VERSION "ECM CAN realtime data broadcast protocol 2016-02-17, section 2.1"

NS_ :

BS_:

BU_: WCM ECM RPI PDM

BO_ 768 PDM_status_group_1: 8 PDM
 SG_ pcba_temp_3 : 63|8@0- (1,0) [-128|127] "deg C"  RPI
 SG_ pcba_temp_2 : 55|8@0- (1,0) [-128|127] "deg C"  RPI
 SG_ pcba_temp_1 : 47|8@0- (1,0) [-128|127] "deg C"  RPI
 SG_ cpu_temp : 39|8@0- (1,0) [-128|127] "deg C"  RPI
 SG_ ac_status : 25|2@0+ (1,0) [0|3] ""  RPI
 SG_ ac_compressor_output : 26|1@0+ (1,0) [0|1] ""  RPI
 SG_ ac_command : 27|1@0+ (1,0) [0|1] ""  RPI
 SG_ blower_output : 29|2@0+ (1,0) [0|3] ""  RPI
 SG_ blower_command : 31|2@0+ (1,0) [0|3] ""  RPI
 SG_ window_state_rightt : 19|4@0+ (1,0) [0|15] ""  RPI
 SG_ window_state_left : 23|4@0+ (1,0) [0|15] ""  RPI
 SG_ wiper_state : 9|2@0+ (1,0) [0|3] ""  RPI
 SG_ turn_state_right : 11|2@0+ (1,0) [0|3] ""  RPI
 SG_ turn_state_left : 13|2@0+ (1,0) [0|3] ""  RPI
 SG_ headlight_state : 15|2@0+ (1,0) [0|3] ""  RPI
 SG_ key_status : 1|2@0+ (1,0) [0|3] ""  RPI
 SG_ power_wake_reason : 4|3@0+ (1,0) [0|7] ""  RPI
 SG_ power_state : 7|3@0+ (1,0) [0|7] ""  RPI

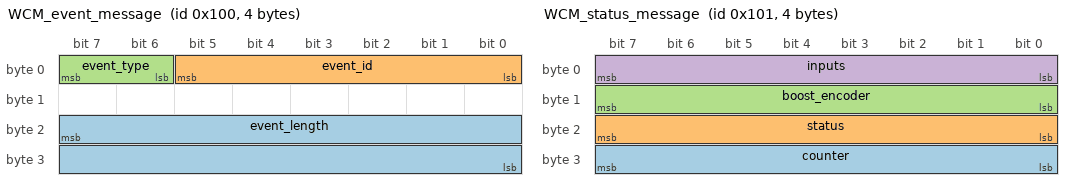
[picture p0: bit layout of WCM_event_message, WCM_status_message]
BO_ 256 WCM_event_message: 4 WCM
 SG_ event_length : 23|16@0+ (1,0) [0|65535] "ms"  RPI,PDM
 SG_ event_id : 5|6@0+ (1,0) [0|7] ""  RPI,PDM
 SG_ event_type : 7|2@0+ (1,0) [0|1] ""  RPI,PDM

BO_ 257 WCM_status_message: 4 WCM
 SG_ counter : 31|8@0+ (1,0) [0|255] ""  RPI,PDM,WCM
 SG_ status : 23|8@0+ (1,0) [0|255] ""  RPI,PDM,WCM
 SG_ boost_encoder : 15|8@0+ (1,0) [0|255] ""  RPI,PDM,WCM
 SG_ inputs : 7|8@0+ (1,0) [0|255] ""  RPI,PDM,WCM

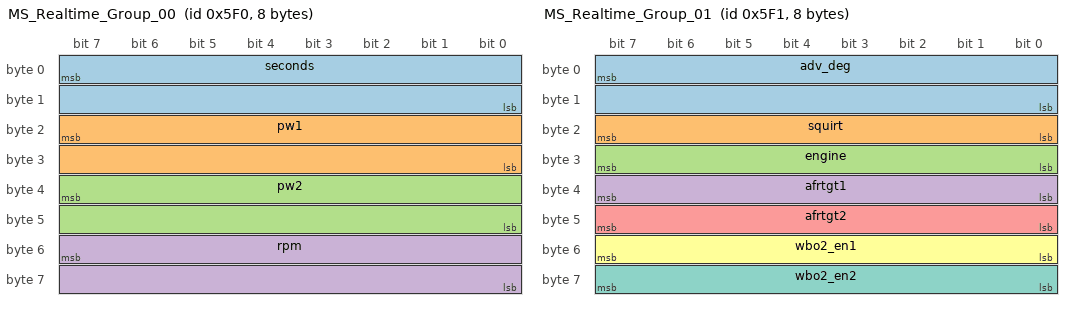
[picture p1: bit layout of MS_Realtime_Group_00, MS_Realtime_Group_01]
BO_ 1520 MS_Realtime_Group_00: 8 ECM
 SG_ seconds : 7|16@0+ (1,0) [0|65535] "s"  RPI
 SG_ pw1 : 23|16@0+ (0.001,0) [0|65.535] "ms"  RPI
 SG_ pw2 : 39|16@0+ (0.001,0) [0|65.535] "ms"  RPI
 SG_ rpm : 55|16@0+ (1,0) [0|65535] "RPM"  RPI

BO_ 1521 MS_Realtime_Group_01: 8 ECM
 SG_ adv_deg : 7|16@0- (0.1,0) [-3276.8|3276.7] "deg BTDC"  RPI
 SG_ squirt : 23|8@0+ (1,0) [0|255] ""  RPI
 SG_ engine : 31|8@0+ (1,0) [0|255] ""  RPI
 SG_ afrtgt1 : 39|8@0+ (0.1,0) [0|25.5] "AFR"  RPI
 SG_ afrtgt2 : 47|8@0+ (0.1,0) [0|25.5] "AFR"  RPI
 SG_ wbo2_en1 : 55|8@0+ (1,0) [0|255] ""  RPI
 SG_ wbo2_en2 : 63|8@0+ (1,0) [0|255] ""  RPI

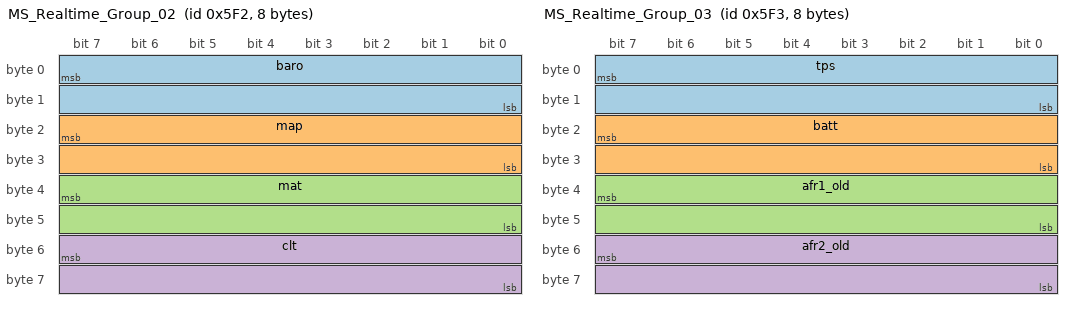
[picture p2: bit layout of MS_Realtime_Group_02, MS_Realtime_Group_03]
BO_ 1522 MS_Realtime_Group_02: 8 ECM
 SG_ baro : 7|16@0- (0.1,0) [-3276.8|3276.7] "kPa"  RPI
 SG_ map : 23|16@0- (0.1,0) [-3276.8|3276.7] "kPa"  RPI
 SG_ mat : 39|16@0- (0.1,0) [-3276.8|3276.7] "deg F"  RPI
 SG_ clt : 55|16@0- (0.1,0) [-3276.8|3276.7] "deg F"  RPI

BO_ 1523 MS_Realtime_Group_03: 8 ECM
 SG_ tps : 7|16@0- (0.1,0) [-3276.8|3276.7] "%"  RPI
 SG_ batt : 23|16@0- (0.1,0) [-3276.8|3276.7] "V"  RPI
 SG_ afr1_old : 39|16@0- (0.1,0) [-3276.8|3276.7] "AFR"  RPI
 SG_ afr2_old : 55|16@0- (0.1,0) [-3276.8|3276.7] "AFR"  RPI

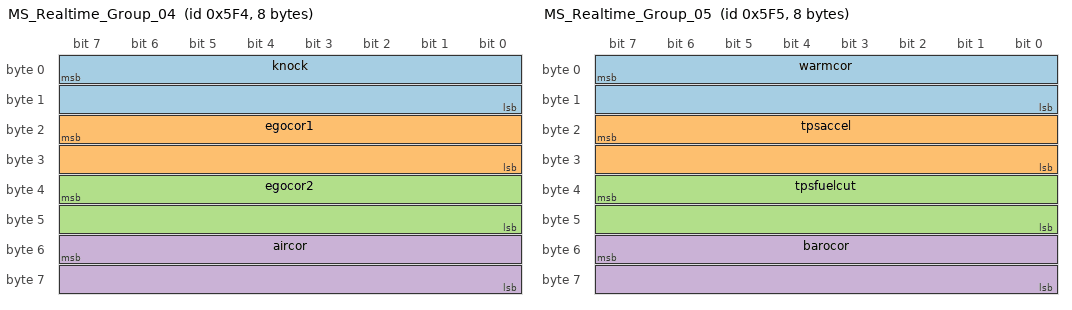
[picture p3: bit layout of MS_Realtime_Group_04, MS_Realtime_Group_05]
BO_ 1524 MS_Realtime_Group_04: 8 ECM
 SG_ knock : 7|16@0- (0.1,0) [-3276.8|3276.7] "%"  RPI
 SG_ egocor1 : 23|16@0- (0.1,0) [-3276.8|3276.7] "%"  RPI
 SG_ egocor2 : 39|16@0- (0.1,0) [-3276.8|3276.7] "%"  RPI
 SG_ aircor : 55|16@0- (0.1,0) [-3276.8|3276.7] "%"  RPI

BO_ 1525 MS_Realtime_Group_05: 8 ECM
 SG_ warmcor : 7|16@0- (0.1,0) [-3276.8|3276.7] "%"  RPI
 SG_ tpsaccel : 23|16@0- (0.1,0) [-3276.8|3276.7] "%"  RPI
 SG_ tpsfuelcut : 39|16@0- (0.1,0) [-3276.8|3276.7] "%"  RPI
 SG_ barocor : 55|16@0- (0.1,0) [-3276.8|3276.7] "%"  RPI

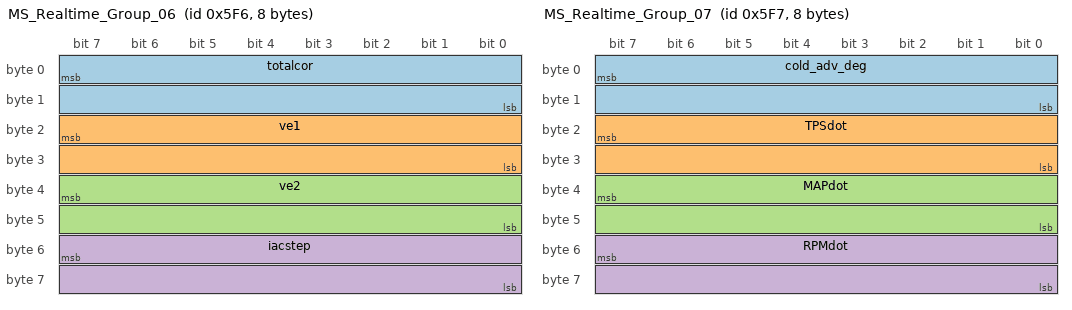
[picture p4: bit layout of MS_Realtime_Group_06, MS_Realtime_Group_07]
BO_ 1526 MS_Realtime_Group_06: 8 ECM
 SG_ totalcor : 7|16@0- (0.1,0) [-3276.8|3276.7] "%"  RPI
 SG_ ve1 : 23|16@0- (0.1,0) [-3276.8|3276.7] "%"  RPI
 SG_ ve2 : 39|16@0- (0.1,0) [-3276.8|3276.7] "%"  RPI
 SG_ iacstep : 55|16@0- (1,0) [-32768|32767] "step"  RPI

BO_ 1527 MS_Realtime_Group_07: 8 ECM
 SG_ cold_adv_deg : 7|16@0- (0.1,0) [-3276.8|3276.7] "deg"  RPI
 SG_ TPSdot : 23|16@0- (0.1,0) [-3276.8|3276.7] "%/s"  RPI
 SG_ MAPdot : 39|16@0- (1,0) [-32768|32767] "kPa/s"  RPI
 SG_ RPMdot : 55|16@0- (10,0) [-327680|327670] "RPM/s"  RPI

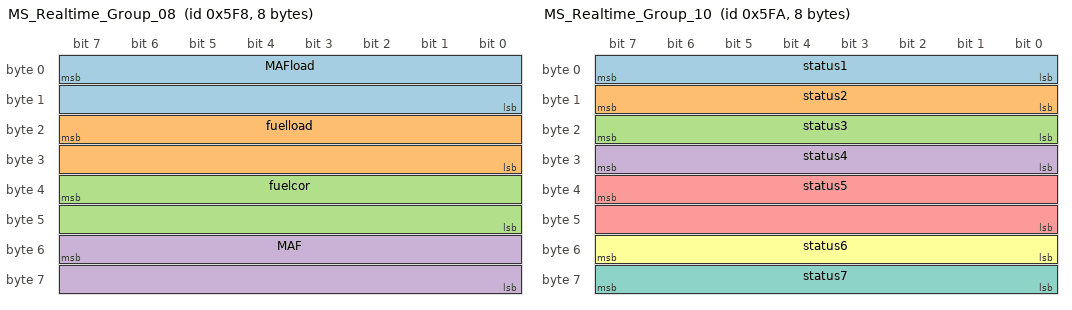
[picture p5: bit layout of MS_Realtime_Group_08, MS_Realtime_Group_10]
BO_ 1528 MS_Realtime_Group_08: 8 ECM
 SG_ MAFload : 7|16@0- (0.1,0) [-3276.8|3276.7] "%"  RPI
 SG_ fuelload : 23|16@0- (0.1,0) [-3276.8|3276.7] "%"  RPI
 SG_ fuelcor : 39|16@0- (0.1,0) [-3276.8|3276.7] "%"  RPI
 SG_ MAF : 55|16@0- (0.01,0) [-327.68|327.67] "g/s"  RPI

BO_ 1530 MS_Realtime_Group_10: 8 ECM
 SG_ status1 : 7|8@0+ (1,0) [0|255] ""  RPI
 SG_ status2 : 15|8@0+ (1,0) [0|255] ""  RPI
 SG_ status3 : 23|8@0+ (1,0) [0|255] ""  RPI
 SG_ status4 : 31|8@0+ (1,0) [0|255] ""  RPI
 SG_ status5 : 39|16@0- (1,0) [-32768|32767] ""  RPI
 SG_ status6 : 55|8@0+ (1,0) [0|255] ""  RPI
 SG_ status7 : 63|8@0+ (1,0) [0|255] ""  RPI

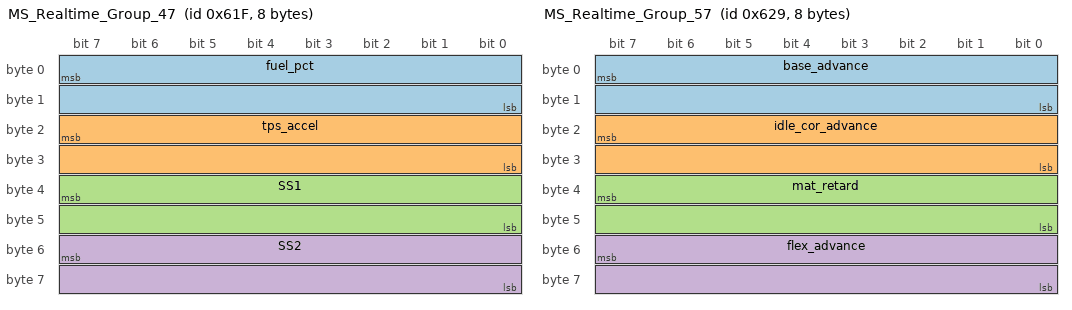
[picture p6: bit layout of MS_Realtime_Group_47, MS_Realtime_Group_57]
BO_ 1567 MS_Realtime_Group_47: 8 ECM
 SG_ fuel_pct : 7|16@0- (0.1,0) [-3276.8|3276.7] "%"  RPI
 SG_ tps_accel : 23|16@0- (0.1,0) [-3276.8|3276.7] "%"  RPI
 SG_ SS1 : 39|16@0+ (10,0) [0|655350] "RPM"  RPI
 SG_ SS2 : 55|16@0+ (10,0) [0|655350] "RPM"  RPI

BO_ 1577 MS_Realtime_Group_57: 8 ECM
 SG_ base_advance : 7|16@0- (0.1,0) [-3276.8|3276.7] "deg"  RPI
 SG_ idle_cor_advance : 23|16@0- (0.1,0) [-3276.8|3276.7] "deg"  RPI
 SG_ mat_retard : 39|16@0- (0.1,0) [-3276.8|3276.7] "deg"  RPI
 SG_ flex_advance : 55|16@0- (0.1,0) [-3276.8|3276.7] "deg"  RPI

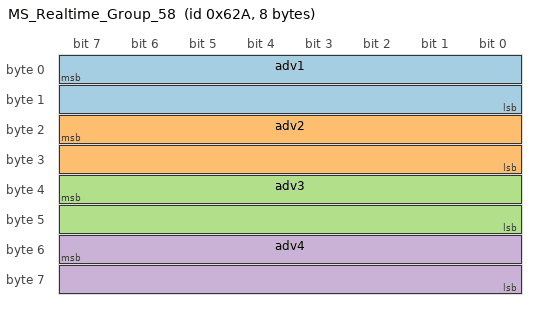
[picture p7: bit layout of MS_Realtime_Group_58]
BO_ 1578 MS_Realtime_Group_58: 8 ECM
 SG_ adv1 : 7|16@0- (0.1,0) [-3276.8|3276.7] "deg"  RPI
 SG_ adv2 : 23|16@0- (0.1,0) [-3276.8|3276.7] "deg"  RPI
 SG_ adv3 : 39|16@0- (0.1,0) [-3276.8|3276.7] "deg"  RPI
 SG_ adv4 : 55|16@0- (0.1,0) [-3276.8|3276.7] "deg"  RPI

CM_ "ECM advanced real-time data broadcast. 11-bit CAN, 500 kbit/s, big-endian. Default base identifier 1520 decimal (0x5F0); message identifier = base + group. Broadcast rates are user-configurable and therefore are not encoded as cycle-time attributes.";
CM_ SG_ 768 key_status "key detection and authentication state";
CM_ SG_ 768 power_wake_reason "reason for pdm wake from sleep / idle mode";
CM_ SG_ 768 power_state "Power FSM state";
CM_ SG_ 256 event_length "Button press duration in milliseconds; valid only on falling-edge events.";
CM_ SG_ 256 event_id "Button ID: 0=down, 1=up, 2=menu, 3=ack, 4=left turn, 5=right turn, 6=wiper, 7=flash.";
CM_ SG_ 256 event_type "Button edge: 0=falling/released, 1=rising/pressed.";
CM_ SG_ 257 counter "Incrementing modulo-256 counter for WCM status messages.";
CM_ SG_ 257 status "WCM health and status bitmask.";
CM_ SG_ 257 boost_encoder "Boost-control dial position.";
CM_ SG_ 257 inputs "Button-state bitmask: bit 0=down, 1=up, 2=menu, 3=ack, 4=left turn, 5=right turn, 6=wiper, 7=flash.";
CM_ SG_ 1520 seconds "Seconds ECU has been on; MS2 support: yes.";
CM_ SG_ 1520 pw1 "Main pulsewidth bank 1; MS2 support: yes.";
CM_ SG_ 1520 pw2 "Main pulsewidth bank 2; MS2 support: yes.";
CM_ SG_ 1520 rpm "Engine RPM; MS2 support: yes.";
CM_ SG_ 1521 adv_deg "Final ignition spark advance; MS2 support: yes.";
CM_ SG_ 1521 squirt "Bitfield of batch fire injector events; MS2 support: yes.";
CM_ SG_ 1521 engine "Bitfield of engine status; MS2 support: yes.";
CM_ SG_ 1521 afrtgt1 "Bank 1 AFR target; MS2 support: yes.";
CM_ SG_ 1521 afrtgt2 "Bank 2 AFR target; MS2 support: yes.";
CM_ SG_ 1521 wbo2_en1 "Not used; MS2 support: yes.";
CM_ SG_ 1521 wbo2_en2 "Not used; MS2 support: yes.";
CM_ SG_ 1522 baro "Barometric pressure; MS2 support: yes.";
CM_ SG_ 1522 map "Manifold air pressure; MS2 support: yes.";
CM_ SG_ 1522 mat "Manifold air temperature; MS2 support: yes.";
CM_ SG_ 1522 clt "Coolant temperature; MS2 support: yes.";
CM_ SG_ 1523 tps "Throttle position; MS2 support: yes.";
CM_ SG_ 1523 batt "Battery voltage; MS2 support: yes.";
CM_ SG_ 1523 afr1_old "AFR1 (deprecated on MS3); MS2 support: yes.";
CM_ SG_ 1523 afr2_old "AFR2 (deprecated on MS3); MS2 support: yes.";
CM_ SG_ 1524 knock "Indication of knock input; MS2 support: yes.";
CM_ SG_ 1524 egocor1 "EGO bank 1 correction; MS2 support: yes.";
CM_ SG_ 1524 egocor2 "EGO bank 2 correction; MS2 support: yes.";
CM_ SG_ 1524 aircor "Air density correction; MS2 support: yes.";
CM_ SG_ 1525 warmcor "Warmup correction; MS2 support: yes.";
CM_ SG_ 1525 tpsaccel "TPS-based acceleration; MS2 support: yes.";
CM_ SG_ 1525 tpsfuelcut "TPS-based fuel cut; MS2 support: yes.";
CM_ SG_ 1525 barocor "Barometric fuel correction; MS2 support: yes.";
CM_ SG_ 1526 totalcor "Total fuel correction; MS2 support: yes.";
CM_ SG_ 1526 ve1 "VE value table/bank 1; MS2 support: yes.";
CM_ SG_ 1526 ve2 "VE value table/bank 2; MS2 support: yes.";
CM_ SG_ 1526 iacstep "Stepper idle step number or PWM idle duty; MS2 support: yes.";
CM_ SG_ 1527 cold_adv_deg "Cold advance; MS2 support: yes.";
CM_ SG_ 1527 TPSdot "Rate of change of TPS; MS2 support: yes.";
CM_ SG_ 1527 MAPdot "Rate of change of MAP; MS2 support: yes.";
CM_ SG_ 1527 RPMdot "Rate of change of RPM; MS2 support: yes.";
CM_ SG_ 1528 MAFload "Synthetic load from MAF; MS2 support: yes.";
CM_ SG_ 1528 fuelload "Load used for fuel table lookup; MS2 support: yes.";
CM_ SG_ 1528 fuelcor "Adjustment to fuel from Flex; MS2 support: yes.";
CM_ SG_ 1528 MAF "Mass air flow (650 g/s scaling shown); MS2 support: yes.";
CM_ SG_ 1530 status1 "ECU status bitfield; MS2 support: yes.";
CM_ SG_ 1530 status2 "ECU status bitfield; MS2 support: yes.";
CM_ SG_ 1530 status3 "ECU status bitfield; MS2 support: yes.";
CM_ SG_ 1530 status4 "Not typically used; MS2 support: yes.";
CM_ SG_ 1530 status5 "Not typically used; MS2 support: yes.";
CM_ SG_ 1530 status6 "ECU status bitfield; MS2 support: no.";
CM_ SG_ 1530 status7 "ECU status bitfield; MS2 support: no.";
CM_ SG_ 1567 fuel_pct "Ethanol content of fuel from Flex sensor; MS2 support: yes.";
CM_ SG_ 1567 tps_accel "TPSdot-based acceleration; MS2 support: no.";
CM_ SG_ 1567 SS1 "Shaft speed 1; MS2 support: no.";
CM_ SG_ 1567 SS2 "Shaft speed 2; MS2 support: no.";
CM_ SG_ 1577 base_advance "Base timing from tables; MS2 support: yes.";
CM_ SG_ 1577 idle_cor_advance "Idle correction advance; MS2 support: yes.";
CM_ SG_ 1577 mat_retard "MAT retard; MS2 support: yes.";
CM_ SG_ 1577 flex_advance "Flex advance; MS2 support: yes.";
CM_ SG_ 1578 adv1 "Timing lookup from table 1; MS2 support: yes.";
CM_ SG_ 1578 adv2 "Timing lookup from table 2; MS2 support: yes.";
CM_ SG_ 1578 adv3 "Timing lookup from table 3; MS2 support: yes.";
CM_ SG_ 1578 adv4 "Timing lookup from table 4; MS2 support: no.";
VAL_ 256 event_id 0 "down" 1 "up" 2 "menu" 3 "ack" 4 "left_turn" 5 "right_turn" 6 "wiper" 7 "flash" ;
VAL_ 256 event_type 0 "falling" 1 "rising" ;
